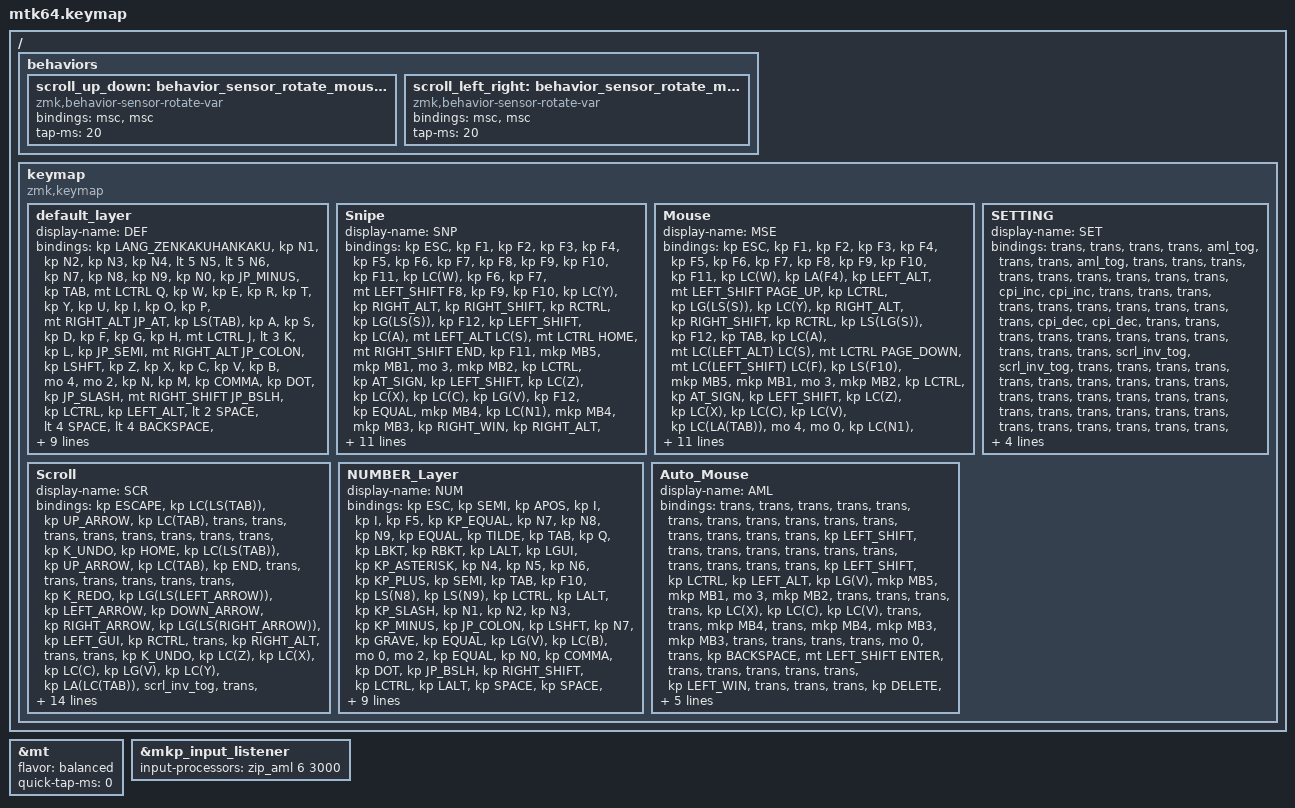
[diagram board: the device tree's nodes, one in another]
#include <input/processors.dtsi>
#include <behaviors.dtsi>
#include <dt-bindings/zmk/keys.h>
#include <dt-bindings/zmk/pointing.h>
#include "keycode_japanese.h"

// スクロール量の設定

#define ZMK_POINTING_DEFAULT_SCRL_VAL 100

&mt {
    flavor = "balanced";
    quick-tap-ms = <0>;
};

&mkp_input_listener { input-processors = <&zip_aml 6 3000>; };

/ {
    behaviors {
        // 垂直スクロール用のbehaviorの設定

        scroll_up_down: behavior_sensor_rotate_mouse_wheel_up_down {
            compatible = "zmk,behavior-sensor-rotate-var";
            #sensor-binding-cells = <2>;
            bindings = <&msc>, <&msc>;

            tap-ms = <20>; // スクロールのタップ時間
        };

        // 水平スクロール用のbehaviorの設定

        scroll_left_right: behavior_sensor_rotate_mouse_wheel_left_right {
            compatible = "zmk,behavior-sensor-rotate-var";
            #sensor-binding-cells = <2>;
            bindings = <&msc>, <&msc>;

            tap-ms = <20>; // スクロールのタップ時間
        };
    };
};

/ {
    keymap {
        compatible = "zmk,keymap";

        default_layer {
            display-name = "DEF";
            bindings = <
&kp LANG_ZENKAKUHANKAKU  &kp N1  &kp N2  &kp N3  &kp N4  &lt 5 N5  &lt 5 N6  &kp N7  &kp N8  &kp N9  &kp N0  &kp JP_MINUS  &kp TAB  &mt LCTRL Q  &kp W  &kp E  &kp R  &kp T  &kp Y  &kp U  &kp I  &kp O  &kp P  &mt RIGHT_ALT JP_AT  &kp LS(TAB)  &kp A  &kp S  &kp D  &kp F  &kp G  &kp H  &mt LCTRL J  &lt 3 K  &kp L  &kp JP_SEMI  &mt RIGHT_ALT JP_COLON  &kp LSHFT  &kp Z  &kp X  &kp C  &kp V  &kp B  &mo 4  &mo 2  &kp N  &kp M  &kp COMMA  &kp DOT  &kp JP_SLASH  &mt RIGHT_SHIFT JP_BSLH  &kp LCTRL  &kp LEFT_ALT  &lt 2 SPACE  &lt 4 SPACE  &lt 4 BACKSPACE  &mt RIGHT_SHIFT ENTER  &mt RIGHT_ALT JP_CARET  &mt RCTRL JP_YEN  &aml_tog  &kp LG(TAB)  &lt 1 LANG_ZENKAKUHANKAKU  &kp LEFT_WIN  &kp ENTER  &tog 2  &lt 4 ESC  &lt 1 DELETE  &mo 1  &mo 2  &mo 3  &mo 1  &mo 2  &mo 3  &mo 1  &mo 2  &mo 3
            >;

            sensor-bindings = <
                &inc_dec_kp LEFT_ARROW RIGHT_ARROW
                &inc_dec_kp UP_ARROW   DOWN_ARROW
            >;
        };

        Snipe {
            display-name = "SNP";
            bindings = <
&kp ESC  &kp F1  &kp F2  &kp F3  &kp F4  &kp F5  &kp F6  &kp F7  &kp F8  &kp F9  &kp F10  &kp F11  &kp LC(W)  &kp F6  &kp F7  &mt LEFT_SHIFT F8  &kp F9  &kp F10  &kp LC(Y)  &kp RIGHT_ALT  &kp RIGHT_SHIFT  &kp RCTRL  &kp LG(LS(S))  &kp F12  &kp LEFT_SHIFT  &kp LC(A)  &mt LEFT_ALT LC(S)  &mt LCTRL HOME  &mt RIGHT_SHIFT END  &kp F11  &mkp MB5  &mkp MB1  &mo 3  &mkp MB2  &kp LCTRL  &kp AT_SIGN  &kp LEFT_SHIFT  &kp LC(Z)  &kp LC(X)  &kp LC(C)  &kp LG(V)  &kp F12  &kp EQUAL  &mkp MB4  &kp LC(N1)  &mkp MB4  &mkp MB3  &kp RIGHT_WIN  &kp RIGHT_ALT  &kp RIGHT_SHIFT  &kp LCTRL  &kp LEFT_ALT  &kp SPACE  &mo 4  &mt LCTRL BACKSPACE  &mt LEFT_SHIFT ENTER  &kp RIGHT_ALT  &kp LCTRL  &none  &kp LA(LC(TAB))  &kp LANG_ZENKAKUHANKAKU  &kp RIGHT_WIN  &trans  &trans  &kp ESC  &mt RIGHT_ALT DELETE  &trans  &trans  &trans  &trans  &trans  &trans  &trans  &trans  &trans
            >;

            sensor-bindings =
                <&scroll_left_right SCRL_LEFT SCRL_RIGHT>,
                <&scroll_up_down SCRL_UP SCRL_DOWN>;
        };

        Mouse {
            display-name = "MSE";
            bindings = <
&kp ESC  &kp F1  &kp F2  &kp F3  &kp F4  &kp F5  &kp F6  &kp F7  &kp F8  &kp F9  &kp F10  &kp F11  &kp LC(W)  &kp LA(F4)  &kp LEFT_ALT  &mt LEFT_SHIFT PAGE_UP  &kp LCTRL  &kp LG(LS(S))  &kp LC(Y)  &kp RIGHT_ALT  &kp RIGHT_SHIFT  &kp RCTRL  &kp LS(LG(S))  &kp F12  &kp TAB  &kp LC(A)  &mt LC(LEFT_ALT) LC(S)  &mt LCTRL PAGE_DOWN  &mt LC(LEFT_SHIFT) LC(F)  &kp LS(F10)  &mkp MB5  &mkp MB1  &mo 3  &mkp MB2  &kp LCTRL  &kp AT_SIGN  &kp LEFT_SHIFT  &kp LC(Z)  &kp LC(X)  &kp LC(C)  &kp LC(V)  &kp LC(LA(TAB))  &mo 4  &mo 0  &kp LC(N1)  &mkp MB4  &mkp MB3  &kp RIGHT_WIN  &kp RIGHT_ALT  &kp RIGHT_SHIFT  &kp LCTRL  &kp LEFT_ALT  &kp SPACE  &mo 4  &mt LCTRL BACKSPACE  &mt LEFT_SHIFT ENTER  &kp RIGHT_ALT  &kp RCTRL  &trans  &trans  &kp ESC  &kp RIGHT_WIN  &trans  &trans  &kp ESC  &mt RIGHT_ALT DELETE  &trans  &trans  &trans  &trans  &trans  &trans  &trans  &trans  &trans
            >;

            sensor-bindings =
                <&inc_dec_kp LEFT_ARROW RIGHT_ARROW>,
                <&inc_dec_kp UP_ARROW DOWN_ARROW>;
        };

        Scroll {
            display-name = "SCR";
            bindings = <
&kp ESCAPE  &kp LC(LS(TAB))  &kp UP_ARROW  &kp LC(TAB)  &trans  &trans  &trans  &trans  &trans  &trans  &trans  &trans  &kp K_UNDO  &kp HOME  &kp LC(LS(TAB))  &kp UP_ARROW  &kp LC(TAB)  &kp END  &trans  &trans  &trans  &trans  &trans  &trans  &kp K_REDO  &kp LG(LS(LEFT_ARROW))  &kp LEFT_ARROW  &kp DOWN_ARROW  &kp RIGHT_ARROW  &kp LG(LS(RIGHT_ARROW))  &kp LEFT_GUI  &kp RCTRL  &trans  &kp RIGHT_ALT  &trans  &trans  &kp K_UNDO  &kp LC(Z)  &kp LC(X)  &kp LC(C)  &kp LG(V)  &kp LC(Y)  &kp LA(LC(TAB))  &scrl_inv_tog  &trans  &kp LC(LEFT_SHIFT)  &trans  &trans  &trans  &trans  &kp LCTRL  &kp LEFT_ALT  &mt LEFT_WIN SPACE  &mt LCTRL SPACE  &mt LS(RCTRL) BACKSPACE  &mt RIGHT_SHIFT ENTER  &trans  &trans  &kp LA(LC(TAB))  &kp LG(TAB)  &kp LEFT_ALT  &mt LG(DELETE) LA(LC(DELETE))  &kp ESC  &kp RIGHT_WIN  &mt LC(LEFT_WIN) ESC  &mt RIGHT_ALT DELETE  &kp ESC  &mt RIGHT_ALT DELETE  &trans  &trans  &trans  &trans  &trans  &trans  &trans
            >;

            sensor-bindings =
                <&inc_dec_kp UP_ARROW DOWN_ARROW>,
                <&inc_dec_kp LEFT_ARROW RIGHT_ARROW>;
        };

        NUMBER_Layer {
            display-name = "NUM";
            bindings = <
&kp ESC  &kp SEMI  &kp APOS  &kp I  &kp I  &kp F5  &kp KP_EQUAL  &kp N7  &kp N8  &kp N9  &kp EQUAL  &kp TILDE  &kp TAB  &kp Q  &kp LBKT  &kp RBKT  &kp LALT  &kp LGUI  &kp KP_ASTERISK  &kp N4  &kp N5  &kp N6  &kp KP_PLUS  &kp SEMI  &kp TAB  &kp F10  &kp LS(N8)  &kp LS(N9)  &kp LCTRL  &kp LALT  &kp KP_SLASH  &kp N1  &kp N2  &kp N3  &kp KP_MINUS  &kp JP_COLON  &kp LSHFT  &kp N7  &kp GRAVE  &kp EQUAL  &kp LG(V)  &kp LC(B)  &mo 0  &mo 2  &kp EQUAL  &kp N0  &kp COMMA  &kp DOT  &kp JP_BSLH  &kp RIGHT_SHIFT  &kp LCTRL  &kp LALT  &kp SPACE  &kp SPACE  &mt RCTRL BACKSPACE  &mt RIGHT_SHIFT ENTER  &kp RIGHT_ALT  &kp RCTRL  &trans  &trans  &kp LANG_ZENKAKUHANKAKU  &kp LEFT_WIN  &trans  &trans  &kp ESC  &kp DELETE  &trans  &trans  &trans  &trans  &trans  &trans  &trans  &trans  &trans
            >;

            sensor-bindings =
                <&inc_dec_kp LEFT_ARROW RIGHT_ARROW>,
                <&inc_dec_kp UP_ARROW RIGHT_ARROW>;
        };

        SETTING {
            display-name = "SET";
            bindings = <
&trans  &trans  &trans  &trans  &aml_tog  &trans  &trans  &aml_tog  &trans  &trans  &trans  &trans  &trans  &trans  &trans  &trans  &trans  &cpi_inc  &cpi_inc  &trans  &trans  &trans  &trans  &trans  &trans  &trans  &trans  &trans  &trans  &cpi_dec  &cpi_dec  &trans  &trans  &trans  &trans  &trans  &trans  &trans  &trans  &trans  &trans  &trans  &scrl_inv_tog  &scrl_inv_tog  &trans  &trans  &trans  &trans  &trans  &trans  &trans  &trans  &trans  &trans  &trans  &trans  &trans  &trans  &trans  &trans  &trans  &trans  &trans  &trans  &trans  &trans  &trans  &trans  &trans  &trans  &trans  &trans  &trans  &trans  &trans
            >;

            sensor-bindings =
                <&inc_dec_kp LEFT_ARROW RIGHT_ARROW>,
                <&inc_dec_kp UP_ARROW DOWN_ARROW>;
        };

        Auto_Mouse {
            display-name = "AML";
            bindings = <
&trans  &trans  &trans  &trans  &trans  &trans  &trans  &trans  &trans  &trans  &trans  &trans  &trans  &trans  &trans  &kp LEFT_SHIFT  &trans  &trans  &trans  &trans  &trans  &trans  &trans  &trans  &trans  &trans  &kp LEFT_SHIFT  &kp LCTRL  &kp LEFT_ALT  &kp LG(V)  &mkp MB5  &mkp MB1  &mo 3  &mkp MB2  &trans  &trans  &trans  &trans  &kp LC(X)  &kp LC(C)  &kp LC(V)  &trans  &trans  &mkp MB4  &trans  &mkp MB4  &mkp MB3  &mkp MB3  &trans  &trans  &trans  &trans  &mo 0  &trans  &kp BACKSPACE  &mt LEFT_SHIFT ENTER  &trans  &trans  &trans  &trans  &trans  &kp LEFT_WIN  &trans  &trans  &trans  &kp DELETE  &trans  &trans  &trans  &trans  &trans  &trans  &trans  &trans  &trans
            >;

            sensor-bindings =
                <&inc_dec_kp LEFT_ARROW RIGHT_ARROW>,
                <&inc_dec_kp UP_ARROW DOWN_ARROW>;
        };
    };
};
